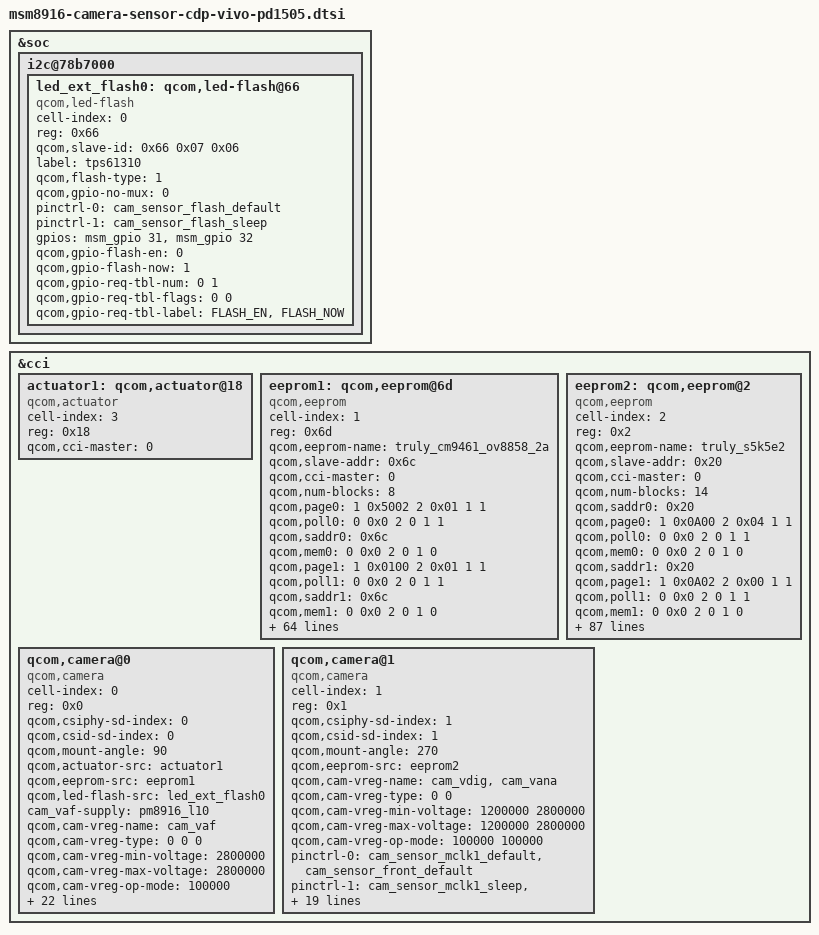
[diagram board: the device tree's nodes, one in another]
/*
 * Copyright (c) 2014, The Linux Foundation. All rights reserved.
 *
 * This program is free software; you can redistribute it and/or modify
 * it under the terms of the GNU General Public License version 2 and
 * only version 2 as published by the Free Software Foundation.
 *
 * This program is distributed in the hope that it will be useful,
 * but WITHOUT ANY WARRANTY; without even the implied warranty of
 * MERCHANTABILITY or FITNESS FOR A PARTICULAR PURPOSE.  See the
 * GNU General Public License for more details.
 */

&soc {
	i2c@78b7000 { /* BLSP1 QUP5 */
            status = "okay";
		led_ext_flash0: qcom,led-flash@66 {
		    cell-index = <0>;
			reg = <0x66>;
			qcom,slave-id = <0x66 0x07 0x06>;
			compatible = "qcom,led-flash";
			label = "tps61310";
			/*qcom,flash-name = "tps61310";*/
			qcom,flash-type = <1>;
			qcom,gpio-no-mux = <0>;
			//qcom,enable_pinctrl;
			pinctrl-names = "cam_flash_default", "cam_flash_suspend";
			pinctrl-0 = <&cam_sensor_flash_default>;
			pinctrl-1 = <&cam_sensor_flash_sleep>;
			
			gpios = <&msm_gpio 31 0>,<&msm_gpio 32 0>;
	        	qcom,gpio-flash-en = <0>;
			qcom,gpio-flash-now = <1>;
			qcom,gpio-req-tbl-num = <0 1>;
			qcom,gpio-req-tbl-flags = <0 0>;
			qcom,gpio-req-tbl-label = "FLASH_EN",
				"FLASH_NOW";
	    };	
	};
};

&cci {
	
	actuator1: qcom,actuator@18 {
		cell-index = <3>;
		reg = <0x18>;
		compatible = "qcom,actuator";
		qcom,cci-master = <0>;
	};

eeprom1: qcom,eeprom@6d{
		cell-index = <1>;
		reg = <0x6d>;
		qcom,eeprom-name = "truly_cm9461_ov8858_2a";
		compatible = "qcom,eeprom";
		qcom,slave-addr = <0x6c>;
		qcom,cci-master = <0>;
		qcom,num-blocks = <8>;

		qcom,page0 = <1 0x5002 2 0x01 1 1>;
		qcom,poll0 = <0 0x0 2 0 1 1>;
		qcom,saddr0 = <0x6c>;
		qcom,mem0 = <0 0x0 2 0 1 0>;

		qcom,page1 = <1 0x0100 2 0x01 1 1>;
		qcom,poll1 = <0 0x0 2 0 1 1>;
		qcom,saddr1 = <0x6c>;
		qcom,mem1 = <0 0x0 2 0 1 0>;

		

		qcom,page2 = <1 0x3d88 2 0x70 1 1>;
		qcom,poll2 = <0 0x0 2 0 1 1>;
		qcom,saddr2 = <0x6c>;
		qcom,mem2 = <0 0x0 2 0 1 0>;

		qcom,page3 = <1 0x3d89 2 0x10 1 1>;
		qcom,poll3 = <0 0x0 2 0 1 1>;
		qcom,saddr3 = <0x6c>;
		qcom,mem3 = <0 0x0 2 0 1 0>;

		qcom,page4 = <1 0x3d8a 2 0x72 1 1>;
		qcom,poll4 = <0 0x0 2 0 1 1>;
		qcom,saddr4 = <0x6c>;
		qcom,mem4 = <0 0x0 2 0 1 0>;

		qcom,page5 = <1 0x3d8b 2 0x0a 1 1>;
		qcom,poll5 = <0 0x0 2 0 1 1>;
		qcom,saddr5 = <0x6c>;
		qcom,mem5 = <0 0x0 2 0 1 0>;
	
		qcom,page6 = <1 0x3d84 2 0xc0 1 1>;
		qcom,pageen6 = <1 0x3d81 2 0x01 1 10>;
		qcom,poll6 = <0 0x0 2 0 1 1>;
		qcom,saddr6 = <0x6c>;
		qcom,mem6 = <507 0x7010 2 0 1 0>;

		qcom,page7 = <1 0x5002 2 0x08 1 1>;
		qcom,poll7 = <0 0x0 2 0 1 1>;
		qcom,saddr7 = <0x6c>;
		qcom,mem7 = <0 0x0 2 0 1 0>;
		
//		cam_vdig-supply = <&pm8916_s4>; //not use
//		cam_vana-supply = <&pm8916_l17>;//not use
//		cam_vio-supply = <&pm8916_l6>;
//		cam_vaf-supply = <&pm8916_l10>;
		qcom,cam-vreg-name = "cam_vana","cam_vdig","cam_vio","cam_vaf";	
		qcom,cam-vreg-type = <0 0 0 0>;
		qcom,cam-vreg-min-voltage = <2850000 1200000  1800000 280000>;
		qcom,cam-vreg-max-voltage = <2850000 1200000 1800000 280000>;
		qcom,cam-vreg-op-mode = <100000   100000 100000 100000>;
		pinctrl-names = "cam_default", "cam_suspend";
		pinctrl-0 = <&cam_sensor_mclk0_default
				&cam_sensor_rear_default
				>;
		pinctrl-1 = <&cam_sensor_mclk0_sleep
					&cam_sensor_rear_sleep
				>;		
		gpios = <&msm_gpio 26 0>,
			<&msm_gpio 35 0>,
			<&msm_gpio 52 0>,
			<&msm_gpio 1 0>,
			<&msm_gpio 16 0>,
			<&msm_gpio 34 0>;
		qcom,gpio-reset = <1>;
		qcom,gpio-vana = <2>;
		qcom,gpio-vdig = <3>;
		qcom,gpio-vio = <4>;
		qcom,gpio-standby = <5>;
		qcom,gpio-req-tbl-num = <0 1 2 3 4 5>;
		qcom,gpio-req-tbl-flags = <1 0 0 0 0 0>;
		
		qcom,csi-lane-assign = <0x4320>;
		qcom,csi-lane-mask = <0x1F>;
		
		qcom,gpio-req-tbl-label = "CAMIF_MCLK",
			"CAM_RESET1",
			"CAM_VANA",
			"CAM_VDIG",
			"CAM_VIO",
			"CAM_STANDBY";		
		qcom,cam-power-seq-type = "sensor_gpio",
			"sensor_gpio","sensor_gpio",  "sensor_clk",
			"sensor_gpio", "sensor_gpio";
		qcom,cam-power-seq-val = 
			"sensor_gpio_vio","sensor_gpio_vana","sensor_gpio_vdig", "sensor_cam_mclk",
			"sensor_gpio_standby",
			"sensor_gpio_reset";
		qcom,cam-power-seq-cfg-val = <1 1 1 23880000 1 1>;
		qcom,cam-power-seq-delay = <1 1 1 5 5 10>;

		qcom,mclk-23880000;
		clocks = <&clock_gcc clk_mclk0_clk_src>,				
			<&clock_gcc clk_gcc_camss_mclk0_clk>;		
		clock-names = "cam_src_clk", "cam_clk";
		
	};

//sub camera truly_s5k5e2 eeprom
eeprom2: qcom,eeprom@2 { 
		cell-index = <2>; 
		reg = <0x2>; 
		qcom,eeprom-name = "truly_s5k5e2"; 
		compatible = "qcom,eeprom"; 

		qcom,slave-addr = <0x20>; 
		qcom,cci-master = <0>; 
		qcom,num-blocks = <14>; 
	
		//BANK 2
		qcom,saddr0 = <0x20>;
		qcom,page0 = <1 0x0A00 2 0x04 1 1>;
		qcom,poll0 = <0 0x0 2 0 1 1>;
		qcom,mem0 = <0 0x0 2 0 1 0>;

		qcom,saddr1 = <0x20>;
		qcom,page1 = <1 0x0A02 2 0x00 1 1>;
		qcom,poll1 = <0 0x0 2 0 1 1>;
		qcom,mem1 = <0 0x0 2 0 1 0>;

		qcom,saddr2 = <0x20>;
		qcom,page2 = <1 0x0A00 2 0x01 1 1>;
		qcom,poll2 = <0 0x0 2 0 1 1>;
		qcom,mem2 = <0 0x0 2 0 1 0>;

		qcom,saddr3 = <0x20>;
		qcom,page3 = <1 0x0A02 2 0x02 1 1>;    //start from bank2
		qcom,pageen3 = <0 0x0 2 0 1 1>;
		qcom,poll3 = <0 0x0 2 0 1 1>;
		qcom,mem3 = <64 0x0A04 2 0 1 0>;

		//BANK 3
		qcom,saddr4 = <0x20>;
		qcom,page4 = <1 0x0A00 2 0x04 1 1>;
		qcom,poll4 = <0 0x0 2 0 1 1>;
		qcom,mem4 = <0 0x0 2 0 1 0>;

		qcom,saddr5 = <0x20>;
		qcom,page5 = <1 0x0A02 2 0x01 1 1>;
		qcom,poll5 = <0 0x0 2 0 1 1>;
		qcom,mem5 = <0 0x0 2 0 1 0>;

		qcom,saddr6 = <0x20>;
		qcom,page6 = <1 0x0A00 2 0x01 1 1>;
		qcom,poll6 = <0 0x0 2 0 1 1>;
		qcom,mem6 = <0 0x0 2 0 1 0>;

		qcom,saddr7 = <0x20>;
		qcom,page7 = <1 0x0A02 2 0x03 1 1>;  
		qcom,pageen7 = <0 0x0 2 0 1 1>;
		qcom,poll7 = <0 0x0 2 0 1 1>;
		qcom,mem7 = <64 0x0A04 2 0 1 0>;
		
		//BANK 4
		qcom,saddr8 = <0x20>;
		qcom,page8 = <1 0x0A00 2 0x04 1 1>;
		qcom,poll8 = <0 0x0 2 0 1 1>;
		qcom,mem8 = <0 0x0 2 0 1 0>;

		qcom,saddr9 = <0x20>;
		qcom,page9 = <1 0x0A02 2 0x02 1 1>;
		qcom,poll9 = <0 0x0 2 0 1 1>;
		qcom,mem9 = <0 0x0 2 0 1 0>;

		qcom,saddr10 = <0x20>;
		qcom,page10 = <1 0x0A00 2 0x01 1 1>;
		qcom,poll10 = <0 0x0 2 0 1 1>;
		qcom,mem10 = <0 0x0 2 0 1 0>;

		qcom,saddr11 = <0x20>;
		qcom,page11 = <1 0x0A02 2 0x04 1 1>;  
		qcom,pageen11 = <0 0x0 2 0 1 1>;
		qcom,poll11 = <0 0x0 2 0 1 1>;
		qcom,mem11 = <64 0x0A04 2 0 1 0>;
	
		//Disable NVM controller
		qcom,saddr12 = <0x20>;
		qcom,page12 = <1 0x0A00 2 0x04 1 1>;
		qcom,poll12 = <0 0x0 2 0 1 1>;
		qcom,mem12 = <0 0x0 2 0 1 0>;

		qcom,saddr13 = <0x20>;
		qcom,page13 = <1 0x0A00 2 0x00 1 1>;
		qcom,poll13 = <0 0x0 2 0 1 1>;
		qcom,mem13 = <0 0x0 2 0 1 0>;
	
	//	cam_vdig-supply = <&pm8916_s4>; //not use
	//	cam_vana-supply = <&pm8916_l17>;//not use
	//	cam_vio-supply = <&pm8916_l6>;
		qcom,cam-vreg-name =   "cam_vdig",  "cam_vana";
		qcom,cam-vreg-type = <0 0>;
		qcom,cam-vreg-min-voltage = <  1200000  2800000 >;
		qcom,cam-vreg-max-voltage = < 1200000  2800000>;
		qcom,cam-vreg-op-mode = <100000  100000>;
		
		qcom,gpio-no-mux = <0>; 
		pinctrl-names = "cam_default", "cam_suspend";
		pinctrl-0 = <&cam_sensor_mclk1_default &cam_sensor_front_default
				>;
		pinctrl-1 = <&cam_sensor_mclk1_sleep &cam_sensor_front_sleep
				>;
				
		gpios = <&msm_gpio 27 0>,
			<&msm_gpio 28 0>,
			<&msm_gpio 33 0>,
			<&msm_gpio 52 0>,
			<&msm_gpio 1 0>,
			<&msm_gpio 16 0>;
		qcom,gpio-reset = <1>;
		qcom,gpio-standby = <2>;
		qcom,gpio-vana = <3>;
		qcom,gpio-vdig = <4>;
		qcom,gpio-vio = <5>;
		qcom,gpio-req-tbl-num = <0 1 2 3 4 5>;
		qcom,gpio-req-tbl-flags = <1 0 0 0 0 0>;
		
		qcom,csi-lane-assign = <0x4320>;
		qcom,csi-lane-mask = <0x07>;
		
		qcom,gpio-req-tbl-label = "CAMIF_MCLK",
			"CAM_RESET",
			"CAM_STANDBY",
			"CAM_VANA1",
			"CAM_VDIG1",
			"CAM_VIO";
		
		qcom,cam-power-seq-type = "sensor_gpio","sensor_gpio", 
		"sensor_gpio", 
		"sensor_clk","sensor_gpio", "sensor_gpio"; 
		qcom,cam-power-seq-val ="sensor_gpio_vio", "sensor_gpio_vdig", 
		"sensor_gpio_vana", "sensor_cam_mclk", "sensor_gpio_reset",
		"sensor_gpio_standby"; 
		
		qcom,cam-power-seq-cfg-val = <1 1  1 23880000 1 1>; 
		qcom,cam-power-seq-delay = <5 5 5 5 10 10 >; 
		
		//status = "ok";
		qcom,mclk-23880000;
		clocks = <&clock_gcc clk_mclk1_clk_src>,
				<&clock_gcc clk_gcc_camss_mclk1_clk>;
		clock-names = "cam_src_clk", "cam_clk";

	}; 


//rear camera ov8858
	qcom,camera@0{
		cell-index = <0>;
		compatible = "qcom,camera";
		reg = <0x0>;
		qcom,csiphy-sd-index = <0>;
		qcom,csid-sd-index = <0>;
		qcom,mount-angle = <90>;
		qcom,actuator-src = <&actuator1>;
		qcom,eeprom-src = <&eeprom1>;
		qcom,led-flash-src = <&led_ext_flash0>;
//		cam_vdig-supply = <&pm8916_s4>; //not use
//		cam_vana-supply = <&pm8916_l17>;//not use
//		cam_vio-supply = <&pm8916_l6>;
		cam_vaf-supply = <&pm8916_l10>;
		qcom,cam-vreg-name = "cam_vaf";
		qcom,cam-vreg-type = <0 0 0>;
		qcom,cam-vreg-min-voltage = <2800000>;
		qcom,cam-vreg-max-voltage = <2800000>;
		qcom,cam-vreg-op-mode = <100000>;
		pinctrl-names = "cam_default", "cam_suspend";
		pinctrl-0 = <&cam_sensor_mclk0_default
				&cam_sensor_rear_default
				>;
		pinctrl-1 = <&cam_sensor_mclk0_sleep
					&cam_sensor_rear_sleep
				>;		
		gpios = <&msm_gpio 26 0>,
			<&msm_gpio 35 0>,
			<&msm_gpio 34 0>,
			<&msm_gpio 52 0>,
			<&msm_gpio 1 0>,
			<&msm_gpio 16 0>;
		qcom,gpio-reset = <1>;
		qcom,gpio-standby = <2>;
		qcom,gpio-vana = <3>;
		qcom,gpio-vdig = <4>;
		qcom,gpio-vio = <5>;
		qcom,gpio-req-tbl-num = <0 1 2 3 4 5>;
		qcom,gpio-req-tbl-flags = <1 0 0 0 0 0>;
		qcom,gpio-req-tbl-label = "CAMIF_MCLK",
			"CAM_RESET1",
			"CAM_STANDBY",
			"CAM_VANA",
			"CAM_VDIG",
			"CAM_VIO";
		qcom,sensor-position = <0>;
		qcom,sensor-mode = <0>;
		qcom,cci-master = <0>;
		qcom,mclk-23880000;
		status = "ok";
		clocks = <&clock_gcc clk_mclk0_clk_src>,				
			<&clock_gcc clk_gcc_camss_mclk0_clk>;		
		clock-names = "cam_src_clk", "cam_clk";
	};

//front camera s5k5e2
	qcom,camera@1 {
		cell-index = <1>;
		compatible = "qcom,camera";
		reg = <0x1>;
		qcom,csiphy-sd-index = <1>;
		qcom,csid-sd-index = <1>;
		qcom,mount-angle = <270>;
		qcom,eeprom-src = <&eeprom2>;
//		cam_vdig-supply = <&pm8916_s4>; //not use
//		cam_vana-supply = <&pm8916_l17>;//not use
		qcom,cam-vreg-name =   "cam_vdig",  "cam_vana";
		qcom,cam-vreg-type = <0 0 >;
		qcom,cam-vreg-min-voltage = <  1200000  2800000 >;
		qcom,cam-vreg-max-voltage = < 1200000  2800000>;
		qcom,cam-vreg-op-mode = <100000  100000>;
		
		pinctrl-names = "cam_default", "cam_suspend";
		pinctrl-0 = <&cam_sensor_mclk1_default &cam_sensor_front_default
				>;
		pinctrl-1 = <&cam_sensor_mclk1_sleep &cam_sensor_front_sleep
				>;
		gpios = <&msm_gpio 27 0>,
			<&msm_gpio 28 0>,
			<&msm_gpio 33 0>,
			<&msm_gpio 52 0>,
			<&msm_gpio 1 0>,
			<&msm_gpio 16 0>;
		qcom,gpio-reset = <1>;
		qcom,gpio-standby = <2>;
		qcom,gpio-vana = <3>;
		qcom,gpio-vdig = <4>;
		qcom,gpio-vio = <5>;
		qcom,gpio-req-tbl-num = <0 1 2 3 4 5>;
		qcom,gpio-req-tbl-flags = <1 0 0 0 0 0>;
		qcom,gpio-req-tbl-label = "CAMIF_MCLK",
			"CAM_RESET",
			"CAM_STANDBY",
			"CAM_VANA1",
			"CAM_VDIG1",
			"CAM_VIO";
		qcom,sensor-position = <1>;		
		qcom,sensor-mode = <0>;		
		qcom,cci-master = <0>;
		qcom,mclk-23880000;
		status = "ok";
		clocks = <&clock_gcc clk_mclk1_clk_src>,
				<&clock_gcc clk_gcc_camss_mclk1_clk>;
		clock-names = "cam_src_clk", "cam_clk";
	};
	
};
